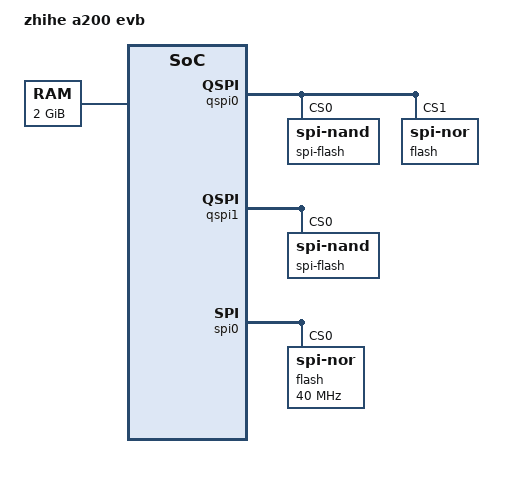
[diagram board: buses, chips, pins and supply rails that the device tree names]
/dts-v1/;

#include "a200-soc.dtsi"

/ {
	model = "zhihe a200 evb";
	compatible = "zhihe,a200-evb";
	#address-cells = <2>;
	#size-cells = <2>;

	aliases {
		spi0 = &spi0;
		spi1 = &qspi0;
		spi2 = &qspi1;
	};

	chosen {
		bootargs = "console=ttyS0,115200";
		stdout-path = "/soc/serial@ffe7014000:115200";
	};

	memory@0 {
		device_type = "memory";
		reg = <0x00 0x00000000 0x00 0x80000000>; /* default 2G, SPL auto check size */
	};

	signature {
		bootph-pre-ram;
		key-dev {
			required = "conf";
			algo = "sha256,rsa2048";
			rsa,r-squared = <0x68bec3f3 0x3bf0d297 0xda573f3d 0x47584cd 0x3a7ed1fa 0xb2f1d671 0x2687be8b 0x996c2ed2 0xfd4fad48 0xaf9c8ab0 0xeeb29007 0xce91965a 0x22de784f 0x8d2aafb5 0x6dc93ee6 0x8e97c1cf 0xdb9af31e 0x55c43026 0x5091bc33 0x5ffa9c32 0x7d46caea 0x1adc3d68 0x9c18457b 0x591655cb 0x96ab0d46 0xd5ef1a3a 0xe3d43abe 0x4a0d964b 0x74881c5e 0x6c9084cf 0xe3b8907a 0xb279100d 0x8969e9d0 0x19bbabda 0xff4b87a5 0xdf994a44 0xe2aea8ab 0x4b56b4b2 0x6dcea2ae 0x33ae87b5 0x4c8dd7f7 0x73ea6081 0x549223be 0x8e7b63d 0xd2e877d5 0xd25af656 0x11d3220 0x4cf03f80 0xa946baa4 0x9ae7c7e9 0x43cb069c 0x27f0afaa 0xc2f7c9f6 0x981cb1a2 0x9d44467a 0x4d5cf5d0 0xfee90fe3 0x5b828c2b 0x3a9dcf53 0xba6956a1 0x5ad91895 0xce5c10f3 0x65036544 0x2e6b64ea>;
			rsa,modulus = <0xb03afddf 0xdec310d6 0xeeb2b63c 0xcf512229 0x6240d68f 0x4252201 0x51ab11cf 0xe904a64b 0x2acf8c95 0xb331ad03 0xcb73eba7 0x4c1e0754 0xe83a5944 0xa5628c98 0x223ea657 0xd535de34 0x318e8b29 0x249cdbcf 0x4469bb38 0xb609701e 0x1f63c622 0x45dc9de9 0xd8affeab 0x6da8361a 0x539c7f0e 0x361cda9f 0xfa877355 0xd2942090 0x75b567c5 0x45db0f86 0xd751153f 0x6c8128f 0x9a394dff 0xf7ac1ad4 0xe47e4033 0x57522063 0x4729ccb4 0x5097f575 0x5e026819 0xc6810b6e 0x69ab698f 0xae49d463 0x8cdc9c5b 0xa217b0d6 0x3e1cbbf5 0xb69bbfe8 0x4aca4f05 0x22dd1e3a 0x19d8142b 0x77b58bbb 0xd3e3dee2 0x409ecaa2 0x86ef3afa 0xdeb63d47 0x5cebb545 0x99c1db5c 0x6217c0a4 0x13f9950b 0xb61c8c00 0x82a527be 0x1328201a 0x9a08e9d1 0xdfded6c1 0xfa5e0d5b>;
			rsa,exponent = <0x00 0x10001>;
			rsa,n0-inverse = <0x8754a52d>;
			rsa,num-bits = <0x800>;
			key-name-hint = "dev";
			u-boot,dm-pre-reloc;
			bootph-pre-ram;
		};
	};
};

&qspi0 {
	num-cs = <1>;
	spi-swap-data = <1>;
	cs-gpio = <&gpio2_port 3 0>;	// QSPI0_NOR_CS

	spi-flash@0 {
		#address-cells = <1>;
		#size-cells = <1>;
		compatible = "spi-nand";
		spi-tx-bus-width = <4>;
		spi-rx-bus-width = <4>;
		reg = <0>;
	};

	flash@1 {
		compatible = "jedec,spi-nor";
		#address-cells = <1>;
		#size-cells = <1>;
		reg = <1>;
		spi-tx-bus-width = <4>;
		spi-rx-bus-width = <4>;
	};
};

&qspi1 {
	num-cs = <1>;
	spi-swap-data = <1>;
	cs-gpio = <&gpio0_port 1 0>;

	spi-flash@0 {
		#address-cells = <1>;
		#size-cells = <1>;
		compatible = "spi-nand";
		spi-tx-bus-width = <4>;
		spi-rx-bus-width = <4>;
		reg = <0>;
	};
};


&spi0 {
	num-cs = <1>;
	cs-gpio = <&gpio2_port 15 0>;

	flash@0 {
		compatible = "jedec,spi-nor";
		spi-max-frequency = <40000000>;
		#address-cells = <1>;
		#size-cells = <1>;
		reg = <0>;
	};
};
